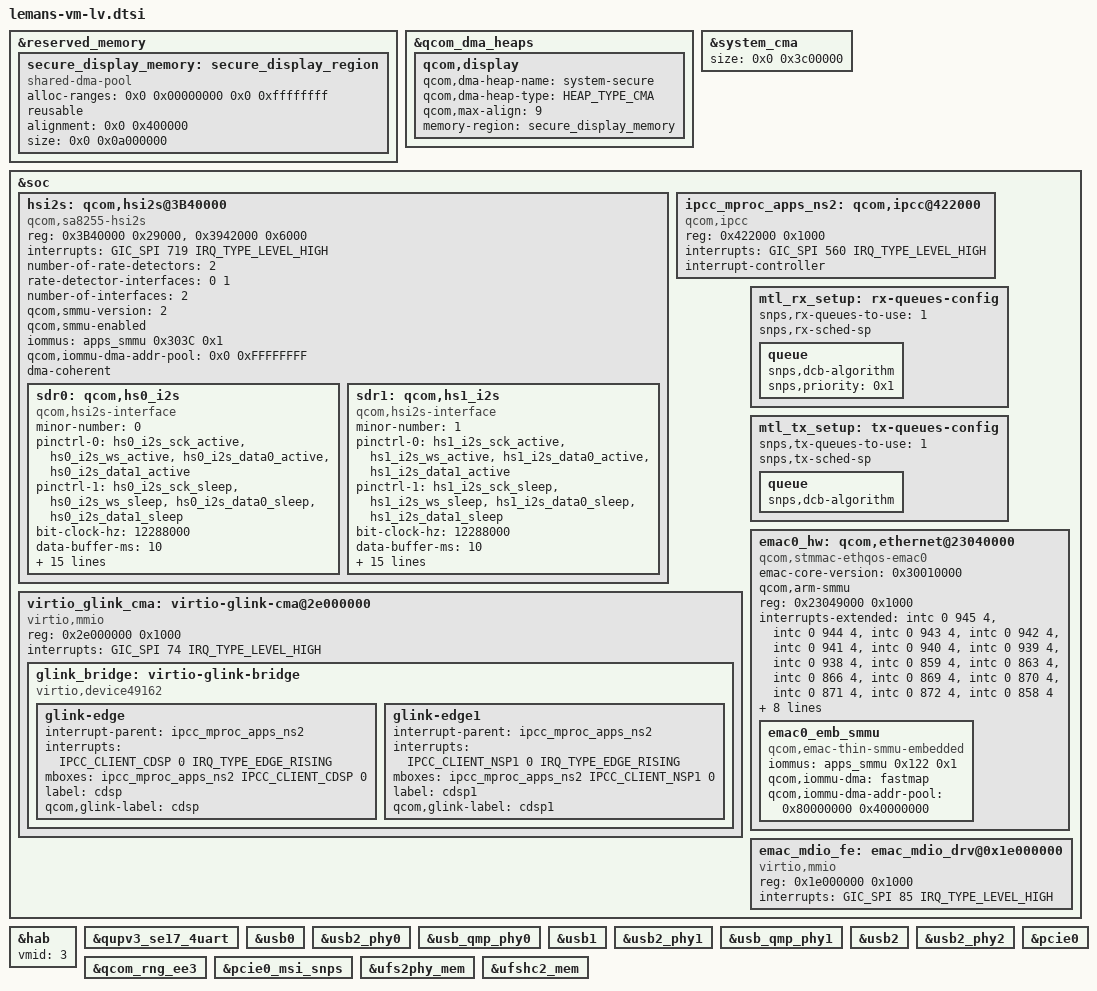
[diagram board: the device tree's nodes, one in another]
#include "lemans-vm-ethernet.dtsi"

&reserved_memory {
	secure_display_memory: secure_display_region {
		compatible = "shared-dma-pool";
		alloc-ranges = <0x0 0x00000000 0x0 0xffffffff>;
		reusable;
		alignment = <0x0 0x400000>;
		size = <0x0 0x0a000000>;
	};
};

&qcom_dma_heaps {
	qcom,display {
		qcom,dma-heap-name = "system-secure";
		qcom,dma-heap-type = <HEAP_TYPE_CMA>;
		qcom,max-align = <9>;
		memory-region = <&secure_display_memory>;
	};
};

&system_cma {
	size = <0x0 0x3c00000>;
};

&soc {
	hsi2s: qcom,hsi2s@3B40000 {
		compatible = "qcom,sa8255-hsi2s", "qcom,hsi2s";
		reg = <0x3B40000 0x29000>,
		    <0x3942000 0x6000>;
		reg-names = "lpa_if", "lpass_core_cc_hs_if";
		interrupts = <GIC_SPI 719 IRQ_TYPE_LEVEL_HIGH>;
		number-of-rate-detectors = <2>;
		rate-detector-interfaces = <0 1>;
		number-of-interfaces = <2>;
		qcom,smmu-version = <2>;
		qcom,smmu-enabled;
		iommus = <&apps_smmu 0x303C 0x1>;
		qcom,iommu-dma-addr-pool = <0x0 0xFFFFFFFF>;
		dma-coherent;

		sdr0: qcom,hs0_i2s {
			compatible = "qcom,hsi2s-interface";
			minor-number = <0>;
			pinctrl-names = "default", "sleep";
			pinctrl-0 = <&hs0_i2s_sck_active
				     &hs0_i2s_ws_active
				     &hs0_i2s_data0_active
				     &hs0_i2s_data1_active>;
			pinctrl-1 = <&hs0_i2s_sck_sleep
				     &hs0_i2s_ws_sleep
				     &hs0_i2s_data0_sleep
				     &hs0_i2s_data1_sleep>;
			bit-clock-hz = <12288000>;
			data-buffer-ms = <10>;
			bit-depth = <32>;
			spkr-channel-count = <2>;
			mic-channel-count = <2>;
			pcm-rate = <2>;
			pcm-sync-src = <0>;
			aux-mode = <0>;
			rpcm-width = <1>;
			tpcm-width = <1>;
			enable-tdm = <1>;
			tdm-rate = <32>;
			tdm-rpcm-width = <16>;
			tdm-tpcm-width = <16>;
			tdm-sync-delay = <2>;
			tdm-inv-sync = <0>;
			pcm-lane-config = <1>;
		};

		sdr1: qcom,hs1_i2s {
			compatible = "qcom,hsi2s-interface";
			minor-number = <1>;
			pinctrl-names = "default", "sleep";
			pinctrl-0 = <&hs1_i2s_sck_active
				     &hs1_i2s_ws_active
				     &hs1_i2s_data0_active
				     &hs1_i2s_data1_active>;
			pinctrl-1 = <&hs1_i2s_sck_sleep
				     &hs1_i2s_ws_sleep
				     &hs1_i2s_data0_sleep
				     &hs1_i2s_data1_sleep>;
			bit-clock-hz = <12288000>;
			data-buffer-ms = <10>;
			bit-depth = <32>;
			spkr-channel-count = <2>;
			mic-channel-count = <2>;
			pcm-rate = <2>;
			pcm-sync-src = <0>;
			aux-mode = <0>;
			rpcm-width = <1>;
			tpcm-width = <1>;
			enable-tdm = <1>;
			tdm-rate = <32>;
			tdm-rpcm-width = <16>;
			tdm-tpcm-width = <16>;
			tdm-sync-delay = <2>;
			tdm-inv-sync = <0>;
			pcm-lane-config = <1>;
		};
	};

	ipcc_mproc_apps_ns2: qcom,ipcc@422000 {
		compatible = "qcom,ipcc";
		reg = <0x422000 0x1000>;
		interrupts = <GIC_SPI 560 IRQ_TYPE_LEVEL_HIGH>;
		interrupt-controller;
		#interrupt-cells = <3>;
		#mbox-cells = <2>;
	};

	virtio_glink_cma: virtio-glink-cma@2e000000 {
		compatible = "virtio,mmio";
		reg = <0x2e000000 0x1000>;
		interrupts = <GIC_SPI 74 IRQ_TYPE_LEVEL_HIGH>;

		glink_bridge: virtio-glink-bridge {
			compatible = "virtio,device49162"; /* VIRTIO_ID: 0xC00A */

			glink-edge {
				interrupt-parent = <&ipcc_mproc_apps_ns2>;
				interrupts = <IPCC_CLIENT_CDSP 0 IRQ_TYPE_EDGE_RISING>;
				mboxes = <&ipcc_mproc_apps_ns2 IPCC_CLIENT_CDSP 0>;
				label = "cdsp";
				qcom,glink-label = "cdsp";
			};

			glink-edge1 {
				interrupt-parent = <&ipcc_mproc_apps_ns2>;
				interrupts = <IPCC_CLIENT_NSP1 0 IRQ_TYPE_EDGE_RISING>;
				mboxes = <&ipcc_mproc_apps_ns2 IPCC_CLIENT_NSP1 0>;
				label = "cdsp1";
				qcom,glink-label = "cdsp1";
			};
		};
	};

	mtl_rx_setup: rx-queues-config {
		snps,rx-queues-to-use = <1>;
		snps,rx-sched-sp;

		queue {
			snps,dcb-algorithm;
			snps,priority = <0x1>;
		};
	};

	mtl_tx_setup: tx-queues-config {
		snps,tx-queues-to-use = <1>;
		snps,tx-sched-sp;
		queue {
			snps,dcb-algorithm;
		};
	};

	emac0_hw: qcom,ethernet@23040000 {
		compatible = "qcom,stmmac-ethqos-emac0";
		emac-core-version = <0x30010000>;
		qcom,arm-smmu;
		reg = <0x23049000 0x1000>;
		reg-names = "stmmaceth";
		interrupts-extended = <&intc 0 945 4>, <&intc 0 944 4>,
			<&intc 0 943 4>, <&intc 0 942 4>,
			<&intc 0 941 4>, <&intc 0 940 4>,
			<&intc 0 939 4>, <&intc 0 938 4>,
			<&intc 0 859 4>,<&intc 0 863 4>,
			<&intc 0 866 4>,<&intc 0 869 4>,
			<&intc 0 870 4>,<&intc 0 871 4>,
			<&intc 0 872 4>,<&intc 0 858 4>;
		interrupt-names = "tx_ch0_intr", "tx_ch1_intr",
			"tx_ch2_intr", "tx_ch3_intr",
			"tx_ch4_intr", "tx_ch5_intr",
			"tx_ch6_intr", "tx_ch7_intr",
			"rx_ch0_intr","rx_ch1_intr",
			"rx_ch2_intr","rx_ch3_intr",
			"rx_ch4_intr","rx_ch5_intr",
			"rx_ch6_intr","rx_ch7_intr";

		snps,tso;
		snps,pbl = <32>;
		mac-address = [00 55 7B B5 7D f7];
		rx-fifo-depth = <4096>;
		tx-fifo-depth = <4096>;
		snps,mtl-rx-config = <&mtl_rx_setup>;
		snps,mtl-tx-config = <&mtl_tx_setup>;
		queue = <1>;
		emac0_emb_smmu: emac0_emb_smmu {
			compatible = "qcom,emac-thin-smmu-embedded";
			iommus = <&apps_smmu 0x122 0x1>;
			qcom,iommu-dma = "fastmap";
			qcom,iommu-dma-addr-pool = <0x80000000 0x40000000>;
		};
	};

	emac_mdio_fe: emac_mdio_drv@0x1e000000 {
		compatible = "virtio,mmio";
		reg =<0x1e000000 0x1000>;
		interrupts = <GIC_SPI 85 IRQ_TYPE_LEVEL_HIGH>;
	};
};

&hab {
	vmid = <3>;
};

&qupv3_se17_4uart {
	status = "okay";
};

&usb0 {
	status = "okay";
};

&usb2_phy0 {
	status = "okay";
};

&usb_qmp_phy0 {
	status = "okay";
};

&usb1 {
	status = "okay";
};

&usb2_phy1 {
	status = "okay";
};

&usb_qmp_phy1 {
	status = "okay";
};

&usb2 {
	status = "okay";
};

&usb2_phy2 {
	status = "okay";
};

&qcom_rng_ee3 {
	status = "okay";
};

&pcie0 {
	status = "ok";
};

&pcie0_msi_snps {
	status = "ok";
};

&ufs2phy_mem {
	status = "ok";
};

&ufshc2_mem {
	status = "ok";
};
